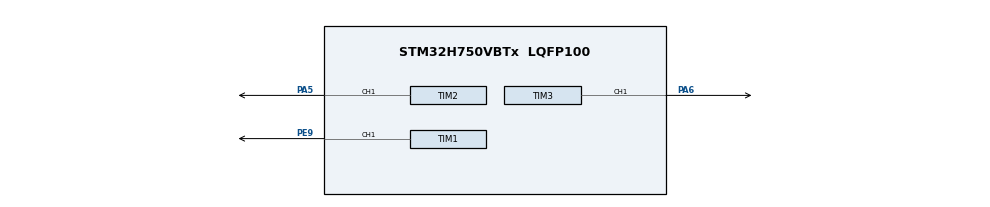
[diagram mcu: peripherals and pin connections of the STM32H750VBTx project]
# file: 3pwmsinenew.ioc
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CORTEX_M7.CPU_DCache=Enabled
CORTEX_M7.CPU_ICache=Enabled
Dma.Request0=TIM1_CH1
Dma.Request1=TIM2_CH1
Dma.Request2=TIM3_CH1
Dma.TIM1_CH1.0.Direction=DMA_MEMORY_TO_PERIPH
Dma.TIM1_CH1.0.EventEnable=DISABLE
Dma.TIM1_CH1.0.FIFOMode=DMA_FIFOMODE_ENABLE
Dma.TIM1_CH1.0.FIFOThreshold=DMA_FIFO_THRESHOLD_FULL
Dma.TIM1_CH1.0.Instance=DMA1_Stream0
Dma.TIM1_CH1.0.MemBurst=DMA_MBURST_SINGLE
Dma.TIM1_CH1.0.MemDataAlignment=DMA_MDATAALIGN_HALFWORD
Dma.TIM1_CH1.0.MemInc=DMA_MINC_ENABLE
Dma.TIM1_CH1.0.Mode=DMA_CIRCULAR
Dma.TIM1_CH1.0.PeriphBurst=DMA_PBURST_SINGLE
Dma.TIM1_CH1.0.PeriphDataAlignment=DMA_PDATAALIGN_HALFWORD
Dma.TIM1_CH1.0.PeriphInc=DMA_PINC_DISABLE
Dma.TIM1_CH1.0.Polarity=HAL_DMAMUX_REQ_GEN_RISING
Dma.TIM1_CH1.0.Priority=DMA_PRIORITY_LOW
Dma.TIM1_CH1.0.RequestNumber=1
Dma.TIM1_CH1.0.SignalID=NONE
Dma.TIM1_CH1.0.SyncEnable=DISABLE
Dma.TIM1_CH1.0.SyncPolarity=HAL_DMAMUX_SYNC_NO_EVENT
Dma.TIM1_CH1.0.SyncRequestNumber=1
Dma.TIM1_CH1.0.SyncSignalID=NONE
Dma.TIM2_CH1.1.Direction=DMA_MEMORY_TO_PERIPH
Dma.TIM2_CH1.1.EventEnable=DISABLE
Dma.TIM2_CH1.1.FIFOMode=DMA_FIFOMODE_ENABLE
Dma.TIM2_CH1.1.FIFOThreshold=DMA_FIFO_THRESHOLD_FULL
Dma.TIM2_CH1.1.Instance=DMA1_Stream1
Dma.TIM2_CH1.1.MemBurst=DMA_MBURST_SINGLE
Dma.TIM2_CH1.1.MemDataAlignment=DMA_MDATAALIGN_WORD
Dma.TIM2_CH1.1.MemInc=DMA_MINC_ENABLE
Dma.TIM2_CH1.1.Mode=DMA_CIRCULAR
Dma.TIM2_CH1.1.PeriphBurst=DMA_PBURST_SINGLE
Dma.TIM2_CH1.1.PeriphDataAlignment=DMA_PDATAALIGN_WORD
Dma.TIM2_CH1.1.PeriphInc=DMA_PINC_DISABLE
Dma.TIM2_CH1.1.Polarity=HAL_DMAMUX_REQ_GEN_RISING
Dma.TIM2_CH1.1.Priority=DMA_PRIORITY_LOW
Dma.TIM2_CH1.1.RequestNumber=1
Dma.TIM2_CH1.1.SignalID=NONE
Dma.TIM2_CH1.1.SyncEnable=DISABLE
Dma.TIM2_CH1.1.SyncPolarity=HAL_DMAMUX_SYNC_NO_EVENT
Dma.TIM2_CH1.1.SyncRequestNumber=1
Dma.TIM2_CH1.1.SyncSignalID=NONE
Dma.TIM3_CH1.2.Direction=DMA_MEMORY_TO_PERIPH
Dma.TIM3_CH1.2.EventEnable=DISABLE
Dma.TIM3_CH1.2.FIFOMode=DMA_FIFOMODE_ENABLE
Dma.TIM3_CH1.2.FIFOThreshold=DMA_FIFO_THRESHOLD_FULL
Dma.TIM3_CH1.2.Instance=DMA1_Stream2
Dma.TIM3_CH1.2.MemBurst=DMA_MBURST_SINGLE
Dma.TIM3_CH1.2.MemDataAlignment=DMA_MDATAALIGN_HALFWORD
Dma.TIM3_CH1.2.MemInc=DMA_MINC_ENABLE
Dma.TIM3_CH1.2.Mode=DMA_CIRCULAR
Dma.TIM3_CH1.2.PeriphBurst=DMA_PBURST_SINGLE
Dma.TIM3_CH1.2.PeriphDataAlignment=DMA_PDATAALIGN_HALFWORD
Dma.TIM3_CH1.2.PeriphInc=DMA_PINC_DISABLE
Dma.TIM3_CH1.2.Polarity=HAL_DMAMUX_REQ_GEN_RISING
Dma.TIM3_CH1.2.Priority=DMA_PRIORITY_LOW
Dma.TIM3_CH1.2.RequestNumber=1
Dma.TIM3_CH1.2.SignalID=NONE
Dma.TIM3_CH1.2.SyncEnable=DISABLE
Dma.TIM3_CH1.2.SyncPolarity=HAL_DMAMUX_SYNC_NO_EVENT
Dma.TIM3_CH1.2.SyncRequestNumber=1
Dma.TIM3_CH1.2.SyncSignalID=NONE
Mcu.Family=STM32H7
Mcu.Name=STM32H750VBTx
Mcu.Package=LQFP100
NVIC.DMA1_Stream0_IRQn=true\:0\:0\:false\:false\:true\:false\:true\:true
NVIC.DMA1_Stream1_IRQn=true\:0\:0\:false\:false\:true\:false\:true\:true
NVIC.DMA1_Stream2_IRQn=true\:0\:0\:false\:false\:true\:false\:true\:true
NVIC.PriorityGroup=NVIC_PRIORITYGROUP_4
PA5.Signal=S_TIM2_CH1_ETR
PA6.Signal=S_TIM3_CH1
PE9.Signal=S_TIM1_CH1
PH0-OSC_IN\ (PH0).Mode=HSE-External-Oscillator
PH0-OSC_IN\ (PH0).Signal=RCC_OSC_IN
PH1-OSC_OUT\ (PH1).Mode=HSE-External-Oscillator
PH1-OSC_OUT\ (PH1).Signal=RCC_OSC_OUT
ProjectManager.HeapSize=0x200
ProjectManager.StackSize=0x400
ProjectManager.TargetToolchain=STM32CubeIDE
RCC.ADCFreq_Value=50390625
RCC.APB1Freq_Value=120000000
RCC.APB2Freq_Value=120000000
RCC.APB3Freq_Value=120000000
RCC.APB4Freq_Value=120000000
RCC.CortexFreq_Value=240000000
RCC.DIVM1=5
RCC.DIVN1=96
RCC.HCLKFreq_Value=120000000
RCC.HPRE=RCC_HCLK_DIV2
RCC.PLLSourceVirtual=RCC_PLLSOURCE_HSE
RCC.SYSCLKFreq_VALUE=240000000
RCC.SYSCLKSource=RCC_SYSCLKSOURCE_PLLCLK
RCC.USBFreq_Value=240000000
SH.S_TIM1_CH1.0=TIM1_CH1,PWM Generation1 CH1
SH.S_TIM2_CH1_ETR.0=TIM2_CH1,PWM Generation1 CH1
SH.S_TIM3_CH1.0=TIM3_CH1,PWM Generation1 CH1
TIM1.AutoReloadPreload=TIM_AUTORELOAD_PRELOAD_ENABLE
TIM1.Channel-Output\ Compare2\ No\ Output=TIM_CHANNEL_2
TIM1.Channel-PWM\ Generation1\ CH1=TIM_CHANNEL_1
TIM1.CounterMode=TIM_COUNTERMODE_CENTERALIGNED2
TIM1.OCMode_2=TIM_OCMODE_ACTIVE
TIM1.Period=30000-1
TIM1.Pulse-Output\ Compare2\ No\ Output=5000
TIM1.Pulse-PWM\ Generation1\ CH1=24000
TIM1.TIM_MasterOutputTrigger=TIM_TRGO_OC2REF
TIM2.AutoReloadPreload=TIM_AUTORELOAD_PRELOAD_ENABLE
TIM2.Channel-Output\ Compare2\ No\ Output=TIM_CHANNEL_2
TIM2.Channel-PWM\ Generation1\ CH1=TIM_CHANNEL_1
TIM2.CounterMode=TIM_COUNTERMODE_CENTERALIGNED2
TIM2.OCMode_2=TIM_OCMODE_ACTIVE
TIM2.Period=30000-1
TIM2.Pulse-Output\ Compare2\ No\ Output=6000
TIM2.Pulse-PWM\ Generation1\ CH1=24000
TIM2.TIM_MasterOutputTrigger=TIM_TRGO_OC2REF
TIM3.AutoReloadPreload=TIM_AUTORELOAD_PRELOAD_ENABLE
TIM3.Channel-PWM\ Generation1\ CH1=TIM_CHANNEL_1
TIM3.CounterMode=TIM_COUNTERMODE_CENTERALIGNED2
TIM3.Period=30000-1
TIM3.Pulse-PWM\ Generation1\ CH1=24000
VP_TIM1_VS_no_output2.Mode=Output Compare2 No Output
VP_TIM2_VS_ClockSourceITR.Mode=TriggerSource_ITR0
VP_TIM2_VS_ControllerModeTrigger.Mode=Trigger Mode
VP_TIM2_VS_no_output2.Mode=Output Compare2 No Output
VP_TIM3_VS_ClockSourceITR.Mode=TriggerSource_ITR1
VP_TIM3_VS_ControllerModeTrigger.Mode=Trigger Mode
board=custom

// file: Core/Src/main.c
/* USER CODE BEGIN Header */
/**
  ******************************************************************************
  * @file           : main.c
  * @brief          : Main program body
  ******************************************************************************
  * @attention
  *
  * Copyright (c) 2023 STMicroelectronics.
  * All rights reserved.
  *
  * This software is licensed under terms that can be found in the LICENSE file
  * in the root directory of this software component.
  * If no LICENSE file comes with this software, it is provided AS-IS.
  *
  ******************************************************************************
  */
/* USER CODE END Header */
#include "main.h"

TIM_HandleTypeDef htim1;
TIM_HandleTypeDef htim2;
TIM_HandleTypeDef htim3;
DMA_HandleTypeDef hdma_tim1_ch1;
DMA_HandleTypeDef hdma_tim2_ch1;
DMA_HandleTypeDef hdma_tim3_ch1;

/* USER CODE BEGIN PV */
#define CCRValue_BufferSize     200

ALIGN_32BYTES (uint32_t DiscontinuousSineCCRValue_Buffer[CCRValue_BufferSize]) =
{
		0,79,158,237,316,395,473,552,631,710,789,867,946,1024,1103,1181,1260,1338,1416,1494,1572,1650,1728,1806,1883,1961,2038,2115,2192,2269,2346,2423,2499,2575,2652,2728,2804,2879,2955,3030,3105,3180,3255,3329,3404,3478,3552,3625,3699,3772,3845,3918,3990,4063,4135,4206,4278,4349,4420,4491,4561,4631,4701,4770,4840,4909,4977,5046,5113,5181,5249,5316,5382,5449,5515,5580,5646,5711,5775,5839,5903,5967,6030,6093,6155,6217,6279,6340,6401,6461,6521,6581,6640,6699,6758,6815,6873,6930,6987,7043,7099,7154,7209,7264,7318,7371,7424,7477,7529,7581,7632,7683,7733,7783,7832,7881,7930,7977,8025,8072,8118,8164,8209,8254,8298,8342,8385,8428,8470,8512,8553,8594,8634,8673,8712,8751,8789,8826,8863,8899,8935,8970,9005,9039,9072,9105,9138,9169,9201,9231,9261,9291,9320,9348,9376,9403,9429,9455,9481,9506,9530,9554,9577,9599,9621,9642,9663,9683,9702,9721,9739,9757,9774,9790,9806,9821,9836,9850,9863,9876,9888,9899,9910,9920,9930,9939,9947,9955,9962,9969,9975,9980,9985,9989,9992,9995,9997,9999,10000,10000
};

/* USER CODE END PV */

void SystemClock_Config(void);
static void MX_GPIO_Init(void);
static void MX_DMA_Init(void);
static void MX_TIM1_Init(void);
static void MX_TIM2_Init(void);
static void MX_TIM3_Init(void);

int main(void)
{

  /* Enable I-Cache---------------------------------------------------------*/
  SCB_EnableICache();

  /* Enable D-Cache---------------------------------------------------------*/
  SCB_EnableDCache();

  /* MCU Configuration--------------------------------------------------------*/

  /* Reset of all peripherals, Initializes the Flash interface and the Systick. */
  HAL_Init();

  /* USER CODE BEGIN Init */
  SCB_CleanDCache_by_Addr((uint32_t *) DiscontinuousSineCCRValue_Buffer, CCRValue_BufferSize );
  /* USER CODE END Init */

  /* Configure the system clock */
  SystemClock_Config();

  /* Initialize all configured peripherals */
  MX_GPIO_Init();
  MX_DMA_Init();
  MX_TIM1_Init();
  MX_TIM2_Init();
  MX_TIM3_Init();
  /* USER CODE BEGIN 2 */

  HAL_TIM_PWM_Start_DMA(&htim1, TIM_CHANNEL_1,(uint32_t *) DiscontinuousSineCCRValue_Buffer, CCRValue_BufferSize);
  HAL_TIM_OC_Start(&htim1, TIM_CHANNEL_2);

  HAL_TIM_PWM_Start_DMA(&htim2, TIM_CHANNEL_1,(uint32_t *) DiscontinuousSineCCRValue_Buffer, CCRValue_BufferSize);
  HAL_TIM_OC_Start(&htim2, TIM_CHANNEL_2);

  HAL_TIM_PWM_Start_DMA(&htim3, TIM_CHANNEL_1, (uint32_t *)DiscontinuousSineCCRValue_Buffer, CCRValue_BufferSize);

  /* USER CODE END 2 */

  /* Infinite loop */
  while (1)
  {

  }
}

void SystemClock_Config(void)
{
  RCC_OscInitTypeDef RCC_OscInitStruct = {0};
  RCC_ClkInitTypeDef RCC_ClkInitStruct = {0};

  /** Supply configuration update enable
  */
  HAL_PWREx_ConfigSupply(PWR_LDO_SUPPLY);

  /** Configure the main internal regulator output voltage
  */
  __HAL_PWR_VOLTAGESCALING_CONFIG(PWR_REGULATOR_VOLTAGE_SCALE2);

  while(!__HAL_PWR_GET_FLAG(PWR_FLAG_VOSRDY)) {}

  /** Initializes the RCC Oscillators according to the specified parameters
  * in the RCC_OscInitTypeDef structure.
  */
  RCC_OscInitStruct.OscillatorType = RCC_OSCILLATORTYPE_HSE;
  RCC_OscInitStruct.HSEState = RCC_HSE_ON;
  RCC_OscInitStruct.PLL.PLLState = RCC_PLL_ON;
  RCC_OscInitStruct.PLL.PLLSource = RCC_PLLSOURCE_HSE;
  RCC_OscInitStruct.PLL.PLLM = 5;
  RCC_OscInitStruct.PLL.PLLN = 96;
  RCC_OscInitStruct.PLL.PLLP = 2;
  RCC_OscInitStruct.PLL.PLLQ = 2;
  RCC_OscInitStruct.PLL.PLLR = 2;
  RCC_OscInitStruct.PLL.PLLRGE = RCC_PLL1VCIRANGE_2;
  RCC_OscInitStruct.PLL.PLLVCOSEL = RCC_PLL1VCOWIDE;
  RCC_OscInitStruct.PLL.PLLFRACN = 0;
  if (HAL_RCC_OscConfig(&RCC_OscInitStruct) != HAL_OK)
  {
    Error_Handler();
  }

  /** Initializes the CPU, AHB and APB buses clocks
  */
  RCC_ClkInitStruct.ClockType = RCC_CLOCKTYPE_HCLK|RCC_CLOCKTYPE_SYSCLK
                              |RCC_CLOCKTYPE_PCLK1|RCC_CLOCKTYPE_PCLK2
                              |RCC_CLOCKTYPE_D3PCLK1|RCC_CLOCKTYPE_D1PCLK1;
  RCC_ClkInitStruct.SYSCLKSource = RCC_SYSCLKSOURCE_PLLCLK;
  RCC_ClkInitStruct.SYSCLKDivider = RCC_SYSCLK_DIV1;
  RCC_ClkInitStruct.AHBCLKDivider = RCC_HCLK_DIV2;
  RCC_ClkInitStruct.APB3CLKDivider = RCC_APB3_DIV1;
  RCC_ClkInitStruct.APB1CLKDivider = RCC_APB1_DIV1;
  RCC_ClkInitStruct.APB2CLKDivider = RCC_APB2_DIV1;
  RCC_ClkInitStruct.APB4CLKDivider = RCC_APB4_DIV1;

  if (HAL_RCC_ClockConfig(&RCC_ClkInitStruct, FLASH_LATENCY_2) != HAL_OK)
  {
    Error_Handler();
  }
}

static void MX_TIM1_Init(void)
{

  TIM_MasterConfigTypeDef sMasterConfig = {0};
  TIM_OC_InitTypeDef sConfigOC = {0};
  TIM_BreakDeadTimeConfigTypeDef sBreakDeadTimeConfig = {0};

  htim1.Instance = TIM1;
  htim1.Init.Prescaler = 0;
  htim1.Init.CounterMode = TIM_COUNTERMODE_CENTERALIGNED2;
  htim1.Init.Period = 30000-1;
  htim1.Init.ClockDivision = TIM_CLOCKDIVISION_DIV1;
  htim1.Init.RepetitionCounter = 0;
  htim1.Init.AutoReloadPreload = TIM_AUTORELOAD_PRELOAD_ENABLE;
  if (HAL_TIM_PWM_Init(&htim1) != HAL_OK)
  {
    Error_Handler();
  }
  if (HAL_TIM_OC_Init(&htim1) != HAL_OK)
  {
    Error_Handler();
  }
  sMasterConfig.MasterOutputTrigger = TIM_TRGO_OC2REF;
  sMasterConfig.MasterOutputTrigger2 = TIM_TRGO2_RESET;
  sMasterConfig.MasterSlaveMode = TIM_MASTERSLAVEMODE_DISABLE;
  if (HAL_TIMEx_MasterConfigSynchronization(&htim1, &sMasterConfig) != HAL_OK)
  {
    Error_Handler();
  }
  sConfigOC.OCMode = TIM_OCMODE_PWM1;
  sConfigOC.Pulse = 24000;
  sConfigOC.OCPolarity = TIM_OCPOLARITY_HIGH;
  sConfigOC.OCNPolarity = TIM_OCNPOLARITY_HIGH;
  sConfigOC.OCFastMode = TIM_OCFAST_DISABLE;
  sConfigOC.OCIdleState = TIM_OCIDLESTATE_RESET;
  sConfigOC.OCNIdleState = TIM_OCNIDLESTATE_RESET;
  if (HAL_TIM_PWM_ConfigChannel(&htim1, &sConfigOC, TIM_CHANNEL_1) != HAL_OK)
  {
    Error_Handler();
  }
  sConfigOC.OCMode = TIM_OCMODE_ACTIVE;
  sConfigOC.Pulse = 5000;
  if (HAL_TIM_OC_ConfigChannel(&htim1, &sConfigOC, TIM_CHANNEL_2) != HAL_OK)
  {
    Error_Handler();
  }
  sBreakDeadTimeConfig.OffStateRunMode = TIM_OSSR_DISABLE;
  sBreakDeadTimeConfig.OffStateIDLEMode = TIM_OSSI_DISABLE;
  sBreakDeadTimeConfig.LockLevel = TIM_LOCKLEVEL_OFF;
  sBreakDeadTimeConfig.DeadTime = 0;
  sBreakDeadTimeConfig.BreakState = TIM_BREAK_DISABLE;
  sBreakDeadTimeConfig.BreakPolarity = TIM_BREAKPOLARITY_HIGH;
  sBreakDeadTimeConfig.BreakFilter = 0;
  sBreakDeadTimeConfig.Break2State = TIM_BREAK2_DISABLE;
  sBreakDeadTimeConfig.Break2Polarity = TIM_BREAK2POLARITY_HIGH;
  sBreakDeadTimeConfig.Break2Filter = 0;
  sBreakDeadTimeConfig.AutomaticOutput = TIM_AUTOMATICOUTPUT_DISABLE;
  if (HAL_TIMEx_ConfigBreakDeadTime(&htim1, &sBreakDeadTimeConfig) != HAL_OK)
  {
    Error_Handler();
  }
  HAL_TIM_MspPostInit(&htim1);

}

static void MX_TIM2_Init(void)
{

  TIM_SlaveConfigTypeDef sSlaveConfig = {0};
  TIM_MasterConfigTypeDef sMasterConfig = {0};
  TIM_OC_InitTypeDef sConfigOC = {0};

  htim2.Instance = TIM2;
  htim2.Init.Prescaler = 0;
  htim2.Init.CounterMode = TIM_COUNTERMODE_CENTERALIGNED2;
  htim2.Init.Period = 30000-1;
  htim2.Init.ClockDivision = TIM_CLOCKDIVISION_DIV1;
  htim2.Init.AutoReloadPreload = TIM_AUTORELOAD_PRELOAD_ENABLE;
  if (HAL_TIM_Base_Init(&htim2) != HAL_OK)
  {
    Error_Handler();
  }
  if (HAL_TIM_PWM_Init(&htim2) != HAL_OK)
  {
    Error_Handler();
  }
  if (HAL_TIM_OC_Init(&htim2) != HAL_OK)
  {
    Error_Handler();
  }
  sSlaveConfig.SlaveMode = TIM_SLAVEMODE_TRIGGER;
  sSlaveConfig.InputTrigger = TIM_TS_ITR0;
  if (HAL_TIM_SlaveConfigSynchro(&htim2, &sSlaveConfig) != HAL_OK)
  {
    Error_Handler();
  }
  sMasterConfig.MasterOutputTrigger = TIM_TRGO_OC2REF;
  sMasterConfig.MasterSlaveMode = TIM_MASTERSLAVEMODE_DISABLE;
  if (HAL_TIMEx_MasterConfigSynchronization(&htim2, &sMasterConfig) != HAL_OK)
  {
    Error_Handler();
  }
  sConfigOC.OCMode = TIM_OCMODE_PWM1;
  sConfigOC.Pulse = 24000;
  sConfigOC.OCPolarity = TIM_OCPOLARITY_HIGH;
  sConfigOC.OCFastMode = TIM_OCFAST_DISABLE;
  if (HAL_TIM_PWM_ConfigChannel(&htim2, &sConfigOC, TIM_CHANNEL_1) != HAL_OK)
  {
    Error_Handler();
  }
  sConfigOC.OCMode = TIM_OCMODE_ACTIVE;
  sConfigOC.Pulse = 6000;
  if (HAL_TIM_OC_ConfigChannel(&htim2, &sConfigOC, TIM_CHANNEL_2) != HAL_OK)
  {
    Error_Handler();
  }
  HAL_TIM_MspPostInit(&htim2);

}

static void MX_TIM3_Init(void)
{

  TIM_SlaveConfigTypeDef sSlaveConfig = {0};
  TIM_MasterConfigTypeDef sMasterConfig = {0};
  TIM_OC_InitTypeDef sConfigOC = {0};

  htim3.Instance = TIM3;
  htim3.Init.Prescaler = 0;
  htim3.Init.CounterMode = TIM_COUNTERMODE_CENTERALIGNED2;
  htim3.Init.Period = 30000-1;
  htim3.Init.ClockDivision = TIM_CLOCKDIVISION_DIV1;
  htim3.Init.AutoReloadPreload = TIM_AUTORELOAD_PRELOAD_ENABLE;
  if (HAL_TIM_Base_Init(&htim3) != HAL_OK)
  {
    Error_Handler();
  }
  if (HAL_TIM_PWM_Init(&htim3) != HAL_OK)
  {
    Error_Handler();
  }
  sSlaveConfig.SlaveMode = TIM_SLAVEMODE_TRIGGER;
  sSlaveConfig.InputTrigger = TIM_TS_ITR1;
  if (HAL_TIM_SlaveConfigSynchro(&htim3, &sSlaveConfig) != HAL_OK)
  {
    Error_Handler();
  }
  sMasterConfig.MasterOutputTrigger = TIM_TRGO_RESET;
  sMasterConfig.MasterSlaveMode = TIM_MASTERSLAVEMODE_DISABLE;
  if (HAL_TIMEx_MasterConfigSynchronization(&htim3, &sMasterConfig) != HAL_OK)
  {
    Error_Handler();
  }
  sConfigOC.OCMode = TIM_OCMODE_PWM1;
  sConfigOC.Pulse = 24000;
  sConfigOC.OCPolarity = TIM_OCPOLARITY_HIGH;
  sConfigOC.OCFastMode = TIM_OCFAST_DISABLE;
  if (HAL_TIM_PWM_ConfigChannel(&htim3, &sConfigOC, TIM_CHANNEL_1) != HAL_OK)
  {
    Error_Handler();
  }
  HAL_TIM_MspPostInit(&htim3);

}

static void MX_DMA_Init(void)
{

  /* DMA controller clock enable */
  __HAL_RCC_DMA1_CLK_ENABLE();

  /* DMA interrupt init */
  /* DMA1_Stream0_IRQn interrupt configuration */
  HAL_NVIC_SetPriority(DMA1_Stream0_IRQn, 0, 0);
  HAL_NVIC_EnableIRQ(DMA1_Stream0_IRQn);
  /* DMA1_Stream1_IRQn interrupt configuration */
  HAL_NVIC_SetPriority(DMA1_Stream1_IRQn, 0, 0);
  HAL_NVIC_EnableIRQ(DMA1_Stream1_IRQn);
  /* DMA1_Stream2_IRQn interrupt configuration */
  HAL_NVIC_SetPriority(DMA1_Stream2_IRQn, 0, 0);
  HAL_NVIC_EnableIRQ(DMA1_Stream2_IRQn);

}

static void MX_GPIO_Init(void)
{

  /* GPIO Ports Clock Enable */
  __HAL_RCC_GPIOH_CLK_ENABLE();
  __HAL_RCC_GPIOA_CLK_ENABLE();
  __HAL_RCC_GPIOE_CLK_ENABLE();

}

void Error_Handler(void)
{
  __disable_irq();
  while (1)
  {
  }
}
